# S1C31W74 register map
Vendor: Epson; Series: S1C31W74; File version: 1.11
CPU: CM0PLUS r0p1, little endian, MPU, no FPU, VTOR, 2 interrupt priority bits
Registers are 16-bit, read-write, reset 0x0 unless marked. A register's access mark holds for its fields unless they carry their own. Offsets are from the block's base; [hi:lo] are bit positions; 'fields as' and 'values as' point back to an identical list.

## SVD2_0 — Supply voltage detector control
Base 0x40000100
Same registers: SVD2_1 0x40000980
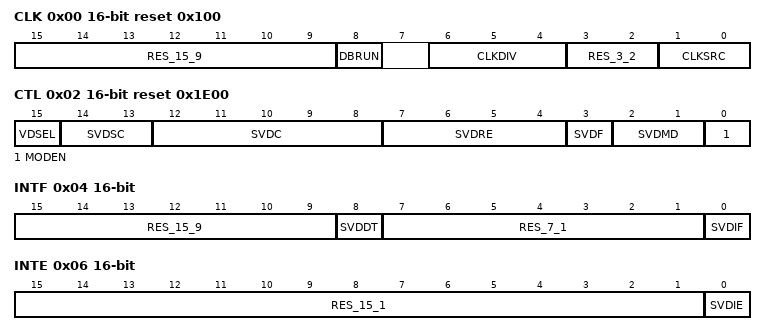
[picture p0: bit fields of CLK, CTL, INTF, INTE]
0x00 CLK reset 0x100 — Clock Control Register
  [15:9] RES_15_9 ro — Reserved bits
  [8] DBRUN — Enable clock on debug mode (can be write protected)
    0=DISABLE; 1=ENABLE
  [6:4] CLKDIV — Clock division select (can be write protected)
  [3:2] RES_3_2 ro — Reserved bits
  [1:0] CLKSRC — Clock source select (can be write protected)
    0=IOSC; 1=OSC1; 2=OSC3; 3=EXOSC
0x02 CTL reset 0x1E00 — SVD Control Register
  [15] VDSEL — Voltage source select (can be write protected)
    0=VDD (Select VDD); 1=EXSVD (Select ESVD)
  [14:13] SVDSC — Condition in intermittent operation mode(can be write protected). Writing take effect when the SVDCTL.SVDMD[1:0] bits are not 0x0
    0=1TIME (1 time in a row); 1=2TIMES (2 times in a row); 2=4TIMES (4 times in a row); 3=8TIMES (8 times in a row)
  [12:8] SVDC — SVD compare voltage (can be write protected).
  [7:4] SVDRE — SVD reset enable(can be write protected).
  [3] SVDF — SVD detect mode
    0=LOWER (Lower detect); 1=UPPER (Upper detect)
  [2:1] SVDMD — SVD intermittent mode
    0=Continious intermittent mode; 1=128MSEC (SVDCLK/128(about 4msec)); 2=256MSEC (SVDCLK/256(about 4msec)); 3=512MSEC (SVDCLK/512(about 4msec))
  [0] MODEN — SVD enable
    0=Disable SVD; 1=Enable SVD
0x04 INTF — Status and Interrupt Flag Register
  [15:9] RES_15_9 ro — Reserved bits
  [8] SVDDT ro — SVD detection monitor
    0=NOT_DETECTED (Power supply voltage (VDD or EXSVD) compare condition not detected); 1=DETECTED (Power supply voltage (VDD or EXSVD) compare condition detected)
  [7:1] RES_7_1 ro — Reserved bits
  [0] SVDIF write-1-clears — SVD interrupt flag
    0=NOT_OCCURED (No cause of interrupt occurred); 1=OCCURED (Cause of interrupt occurred)
0x06 INTE — Interrupt Enable Register
  [15:1] RES_15_1 ro — Reserved bits
  [0] SVDIE — SVD interrupt enable
    0=DISABLE; 1=ENABLE

## T16_0 — 16 Timer / Counter, counting up or down from different sources
Base 0x40000160
Same registers: T16_1 0x400003A0, T16_3 0x40000480, T16_2 0x40000680
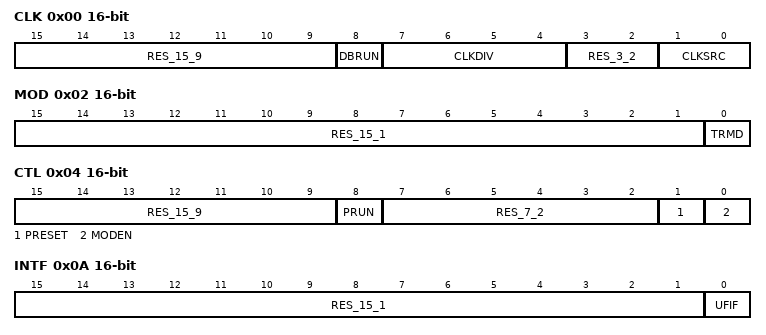
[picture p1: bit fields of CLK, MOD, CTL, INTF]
0x00 CLK — Clock Control Register
  [15:9] RES_15_9 ro — Reserved bits
  [8] DBRUN — RUN
    0=STOP (Timer is stopped and does not operate); 1=RUN (Timer is started and operates)
  [7:4] CLKDIV — Clock division ratio
  [3:2] RES_3_2 ro — Reserved bits
  [1:0] CLKSRC — Clock source select
    3=EXOSC (External OSC); 2=OSC3; 0=IOSC
0x02 MOD — Mode Register
  [15:1] RES_15_1 ro — Reserved bits
  [0] TRMD — Repeat mode select
    1=ONE_SHOT; 0=REPEAT
0x04 CTL — Channel 0 Control Register
  [15:9] RES_15_9 ro — Reserved bits
  [8] PRUN — Run Stop bit
    values as CLK.DBRUN
  [7:2] RES_7_2 ro — Reserved bits
  [1] PRESET — Timer reset
    on write: 0=NO_ACTION (No action when written, no reset when read); 1=RESET (Reset timer when written, reset pending when read) | on read: 0=NO_RESET (No action when written, no reset when read); 1=RESET_PENDING (Reset timer when written, reset pending when read)
  [0] MODEN — Timer enable
    0=DISABLE (Disable timer); 1=ENABLE (Enable timer)
0x06 TR — Reload Data Register
  [15:0] TR — Timer reload value
0x08 TC ro — Counter Data Register
  [15:0] TC — Timer count value
0x0A INTF — Interrupt Flag Register
  [15:1] RES_15_1 ro — Reserved bits
  [0] UFIF write-1-clears — Underflow interrupt flag
    0=NOT_OCCURED (No cause of interrupt occurred); 1=OCCURED (Cause of interrupt occurred)
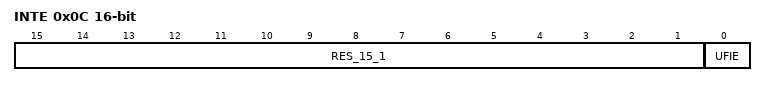
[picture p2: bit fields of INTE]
0x0C INTE — Interrupt Enable Register
  [15:1] RES_15_1 ro — Reserved bits
  [0] UFIE — Underflow interrupt enable
    0=DISABLE; 1=ENABLE

## FLASHC — Flash controller
Base 0x400001B0
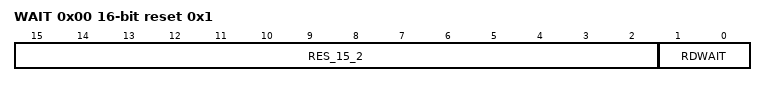
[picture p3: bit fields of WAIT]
0x00 WAIT reset 0x1 — Flash Read Cycle Register
  [15:2] RES_15_2 ro — Reserved bits
  [1:0] RDWAIT — RdCycle Number of cycles (can be write protected)
